VERSION ""

NS_ :

BS_:

BU_:

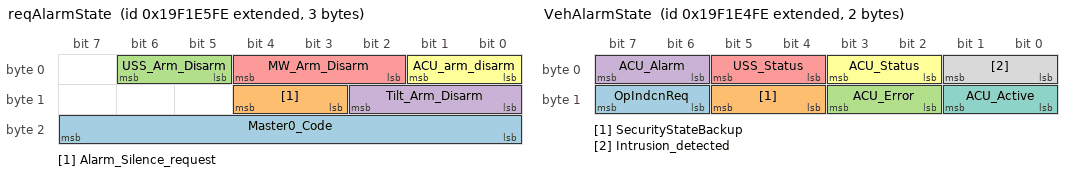
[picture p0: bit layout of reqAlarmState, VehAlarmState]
BO_ 2582767102 reqAlarmState: 3 Vector__XXX
 SG_ Master0_Code : 16|8@1+ (1,0) [0|255] "" Vector__XXX
 SG_ Alarm_Silence_request : 11|2@1+ (1,0) [0|3] "" Vector__XXX
 SG_ USS_Arm_Disarm : 5|2@1+ (1,0) [0|3] "" Vector__XXX
 SG_ Tilt_Arm_Disarm : 8|3@1+ (1,0) [0|7] "" Vector__XXX
 SG_ MW_Arm_Disarm : 2|3@1+ (1,0) [0|7] "" Vector__XXX
 SG_ ACU_arm_disarm : 0|2@1+ (1,0) [0|3] "" Vector__XXX

BO_ 2582766846 VehAlarmState: 2 Vector__XXX
 SG_ OpIndcnReq : 14|2@1+ (1,0) [0|3] "" Vector__XXX
 SG_ SecurityStateBackup : 12|2@1+ (1,0) [0|0] "" Vector__XXX
 SG_ ACU_Error : 10|2@1+ (1,0) [0|0] "" Vector__XXX
 SG_ ACU_Alarm : 6|2@1+ (1,0) [0|3] "" Vector__XXX
 SG_ USS_Status : 4|2@1+ (1,0) [0|3] "" Vector__XXX
 SG_ ACU_Status : 2|2@1+ (1,0) [0|3] "" Vector__XXX
 SG_ ACU_Active : 8|2@1+ (1,0) [0|3] "" Vector__XXX
 SG_ Intrusion_detected : 0|2@1+ (1,0) [0|3] "-" Vector__XXX

CM_ "$File: //depot/auto/dbc/Software_Modules/Safety_System/Alarm_system/0.1.2.0/ALARMDRV.dbc $
$Change: 215982 $
$DateTime: 2024/08/21 10:10:27 $
$Revision: #1 $";
CM_ SG_ 2582767102 Master0_Code "Master code value ";
CM_ SG_ 2582767102 Alarm_Silence_request "Silence alarm request";
CM_ SG_ 2582767102 USS_Arm_Disarm "Ultrasonic alarm arm or disarm request";
CM_ SG_ 2582767102 Tilt_Arm_Disarm "Tilt alarm arm or disarm request ";
CM_ SG_ 2582767102 MW_Arm_Disarm "MW alarm arm or disarm request ";
CM_ SG_ 2582767102 ACU_arm_disarm "ACU arm disarm request";
CM_ SG_ 2582766846 ACU_Alarm "State of alarm";
CM_ SG_ 2582766846 USS_Status "Arm or disarm USS status ";
CM_ SG_ 2582766846 ACU_Status "Arm or disarm ACU status ";
CM_ SG_ 2582766846 ACU_Active "State of siren ";
CM_ SG_ 2582766846 Intrusion_detected "State of intrusion detection
";
BA_DEF_ SG_  "SigType" ENUM  "Default","Range","RangeSigned","ASCII","Discrete","Control","ReferencePGN","DTC","StringDelimiter","StringLength","StringLengthControl","MessageCounter","MessageChecksum";
BA_DEF_ SG_  "GenSigEVName" STRING ;
BA_DEF_ SG_  "GenSigILSupport" ENUM  "No","Yes";
BA_DEF_ SG_  "GenSigSendType" ENUM  "Cyclic","OnWrite","OnWriteWithRepetition","OnChange","OnChangeWithRepetition","IfActive","IfActiveWithRepetition","NoSigSendType";
BA_DEF_ BO_  "SendOnChange" ENUM  "No","Yes";
BA_DEF_ SG_  "GenSigStartValue" INT 0 2147483647;
BA_DEF_ BO_  "GenMsgDelayTime" INT 0 1000;
BA_DEF_ BO_  "GenMsgILSupport" ENUM  "No","Yes";
BA_DEF_ BU_  "NmStationAddress" INT 0 255;
BA_DEF_ BO_  "GenMsgSendType" ENUM  "cyclic","NotUsed","IfActive","NotUsed","NotUsed","NotUsed","NotUsed","NotUsed","noMsgSendType";
BA_DEF_ BO_  "GenMsgRequestable" INT 0 1;
BA_DEF_ BO_  "GenMsgCycleTime" INT 0 3600000;
BA_DEF_ BO_  "Producer" STRING ;
BA_DEF_  "DBName" STRING ;
BA_DEF_  "BusType" STRING ;
BA_DEF_  "ProtocolType" STRING ;
BA_DEF_ BO_  "VFrameFormat" ENUM  "StandardCAN","ExtendedCAN","reserved","J1939PG";
BA_DEF_DEF_  "SigType" "Default";
BA_DEF_DEF_  "GenSigEVName" "Env@Nodename_@Signame";
BA_DEF_DEF_  "GenSigILSupport" "Yes";
BA_DEF_DEF_  "GenSigSendType" "NoSigSendType";
BA_DEF_DEF_  "SendOnChange" "No";
BA_DEF_DEF_  "GenSigStartValue" 0;
BA_DEF_DEF_  "GenMsgDelayTime" 0;
BA_DEF_DEF_  "GenMsgILSupport" "Yes";
BA_DEF_DEF_  "NmStationAddress" 254;
BA_DEF_DEF_  "GenMsgSendType" "noMsgSendType";
BA_DEF_DEF_  "GenMsgRequestable" 1;
BA_DEF_DEF_  "GenMsgCycleTime" 0;
BA_DEF_DEF_  "DBName" "";
BA_DEF_DEF_  "BusType" "CAN";
BA_DEF_DEF_  "ProtocolType" "J1939";
BA_DEF_DEF_  "VFrameFormat" "J1939PG";
BA_ "DBName" "ALARMDRV";
BA_ "GenMsgSendType" BO_ 2582767102 0;
BA_ "SendOnChange" BO_ 2582767102 1;
BA_ "GenMsgCycleTime" BO_ 2582767102 1000;
BA_ "GenMsgDelayTime" BO_ 2582766846 100;
BA_ "SendOnChange" BO_ 2582766846 1;
BA_ "GenMsgCycleTime" BO_ 2582766846 1000;
BA_ "GenMsgSendType" BO_ 2582766846 0;
BA_ "GenSigStartValue" SG_ 2582767102 Alarm_Silence_request 3;
BA_ "GenSigStartValue" SG_ 2582767102 USS_Arm_Disarm 3;
BA_ "GenSigStartValue" SG_ 2582767102 Tilt_Arm_Disarm 5;
BA_ "GenSigStartValue" SG_ 2582767102 MW_Arm_Disarm 5;
BA_ "GenSigStartValue" SG_ 2582767102 ACU_arm_disarm 3;
BA_ "GenSigStartValue" SG_ 2582766846 ACU_Alarm 3;
BA_ "GenSigStartValue" SG_ 2582766846 USS_Status 3;
BA_ "GenSigStartValue" SG_ 2582766846 ACU_Status 3;
BA_ "GenSigStartValue" SG_ 2582766846 ACU_Active 3;
BA_ "GenSigStartValue" SG_ 2582766846 Intrusion_detected 3;
BA_ "Producer" BO_ 2582766846 "SECSYS";
VAL_ 2582767102 Alarm_Silence_request 3 "Not_Available" 2 "Error" 1 "SilenceRequested" 0 "NoSilenceRequested" ;
VAL_ 2582767102 USS_Arm_Disarm 3 "Not_Available" 2 "Error" 1 "USS_arm" 0 "USS_disarm" ;
VAL_ 2582767102 Tilt_Arm_Disarm 5 "Not_Available" 4 "Error" 3 "Extra1" 2 "Extra0" 1 "Tilt_present_arm" 0 "Tilt_present _disarm" ;
VAL_ 2582767102 MW_Arm_Disarm 5 "Not_Available" 4 "Error" 3 "MW_present_arm" 2 "MW_present_disarm" 1 "MW_not_present" 0 "MW_not_present" ;
VAL_ 2582767102 ACU_arm_disarm 3 "Not_Available" 2 "Error" 1 "ACU_arm" 0 "ACU_disarm" ;
VAL_ 2582766846 OpIndcnReq 3 "Not available" 2 "Error" 1 "Indication required" 0 "No indication required" ;
VAL_ 2582766846 SecurityStateBackup 3 "Not_Available" 2 "Reserved" 1 "Compromised" 0 "Not Compromised" ;
VAL_ 2582766846 ACU_Error 3 "Not_Available" 2 "Reserved" 1 "Error" 0 "No Error" ;
VAL_ 2582766846 ACU_Alarm 3 "Not_Available" 2 "Error" 1 "Alarm_on" 0 "Alarm_off" ;
VAL_ 2582766846 USS_Status 3 "Not_Available" 2 "Error" 1 "Armed" 0 "Disarmed" ;
VAL_ 2582766846 ACU_Status 3 "NA" 2 "Error" 1 "Armed" 0 "Disarmed" ;
VAL_ 2582766846 ACU_Active 3 "Not_Available" 2 "Error" 1 "Siren_on" 0 "Siren_off" ;
VAL_ 2582766846 Intrusion_detected 3 "N/A" 2 "Reserved" 1 "Intrusion_detected " 0 "Intrusion_not_detected " ;
